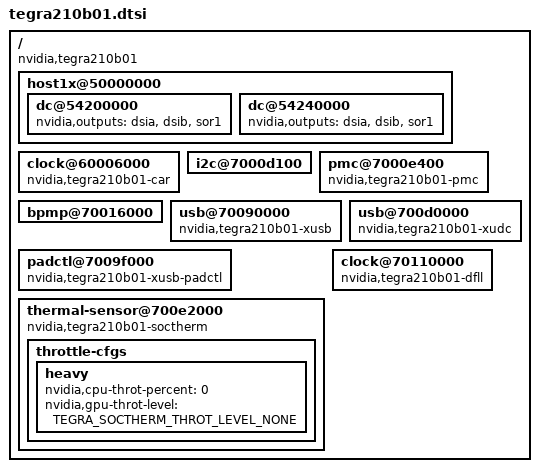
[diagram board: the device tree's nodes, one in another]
// SPDX-License-Identifier: GPL-2.0
#include "tegra210.dtsi"

/ {
	compatible = "nvidia,tegra210b01", "nvidia,tegra210";

	host1x@50000000 {
		/delete-node/ sor@54540000;
		/delete-node/ dpaux@545c0000;

		dc@54200000 {
			nvidia,outputs = <&dsia &dsib &sor1>;
		};

		dc@54240000 {
			nvidia,outputs = <&dsia &dsib &sor1>;
		};
	};

	clock@60006000 {
		compatible = "nvidia,tegra210b01-car";
	};

	i2c@7000d100 {
		/delete-property/ pinctrl-0;
		/delete-property/ pinctrl-1;
		/delete-property/ pinctrl-names;
	};

	pmc@7000e400 {
		compatible = "nvidia,tegra210b01-pmc";
	};

	bpmp@70016000 {
		status = "okay";
	};

	usb@70090000 {
		compatible = "nvidia,tegra210b01-xusb";
	};

	padctl@7009f000 {
		compatible = "nvidia,tegra210b01-xusb-padctl";
	};

	usb@700d0000 {
		compatible = "nvidia,tegra210b01-xudc";
	};

	thermal-sensor@700e2000 {
		compatible = "nvidia,tegra210b01-soctherm";

		throttle-cfgs {
			heavy {
				nvidia,cpu-throt-percent = <0>;
				nvidia,gpu-throt-level = <TEGRA_SOCTHERM_THROT_LEVEL_NONE>;
			};
		};
	};

	clock@70110000 {
		compatible = "nvidia,tegra210b01-dfll";
	};
};
